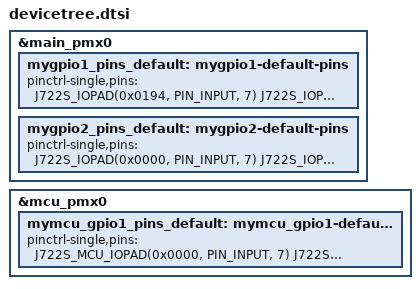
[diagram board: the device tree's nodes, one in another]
/* This file was auto-generated by TI PinMux on 6/7/2024 at 3:31:34 PM. */
/* This file should only be used as a reference. Some pins/peripherals, */
/* depending on your use case, may need additional configuration. */

&main_pmx0 {
	mygpio1_pins_default: mygpio1-default-pins {
		pinctrl-single,pins = <
			J722S_IOPAD(0x0194, PIN_INPUT, 7) /* (A25) MCASP0_AXR3.GPIO1_7 */
			J722S_IOPAD(0x0198, PIN_INPUT, 7) /* (A26) MCASP0_AXR2.GPIO1_8 */
			J722S_IOPAD(0x019c, PIN_INPUT, 7) /* (B25) MCASP0_AXR1.GPIO1_9 */
			J722S_IOPAD(0x01a0, PIN_INPUT, 7) /* (F23) MCASP0_AXR0.GPIO1_10 */
			J722S_IOPAD(0x01a4, PIN_INPUT, 7) /* (D25) MCASP0_ACLKX.GPIO1_11 */
			J722S_IOPAD(0x01a8, PIN_INPUT, 7) /* (C26) MCASP0_AFSX.GPIO1_12 */
			J722S_IOPAD(0x01ac, PIN_INPUT, 7) /* (C27) MCASP0_AFSR.GPIO1_13 */
			J722S_IOPAD(0x01b0, PIN_INPUT, 7) /* (F24) MCASP0_ACLKR.GPIO1_14 */
			J722S_IOPAD(0x01b4, PIN_INPUT, 7) /* (B20) SPI0_CS0.GPIO1_15 */
			J722S_IOPAD(0x01b8, PIN_INPUT, 7) /* (C20) SPI0_CS1.GPIO1_16 */
			J722S_IOPAD(0x01bc, PIN_INPUT, 7) /* (D20) SPI0_CLK.GPIO1_17 */
			J722S_IOPAD(0x01c0, PIN_INPUT, 7) /* (E19) SPI0_D0.GPIO1_18 */
			J722S_IOPAD(0x01c4, PIN_INPUT, 7) /* (E20) SPI0_D1.GPIO1_19 */
			J722S_IOPAD(0x01c8, PIN_INPUT, 7) /* (F19) UART0_RXD.GPIO1_20 */
			J722S_IOPAD(0x01cc, PIN_INPUT, 7) /* (F20) UART0_TXD.GPIO1_21 */
			J722S_IOPAD(0x01d0, PIN_INPUT, 7) /* (E22) UART0_CTSn.GPIO1_22 */
			J722S_IOPAD(0x01d4, PIN_INPUT, 7) /* (B21) UART0_RTSn.GPIO1_23 */
			J722S_IOPAD(0x01d8, PIN_INPUT, 7) /* (D22) MCAN0_TX.GPIO1_24 */
			J722S_IOPAD(0x01dc, PIN_INPUT, 7) /* (C22) MCAN0_RX.GPIO1_25 */
			J722S_IOPAD(0x01e0, PIN_INPUT, 7) /* (D23) I2C0_SCL.GPIO1_26 */
			J722S_IOPAD(0x01e4, PIN_INPUT, 7) /* (B22) I2C0_SDA.GPIO1_27 */
			J722S_IOPAD(0x01e8, PIN_INPUT, 7) /* (C24) I2C1_SCL.GPIO1_28 */
			J722S_IOPAD(0x01ec, PIN_INPUT, 7) /* (A22) I2C1_SDA.GPIO1_29 */
			J722S_IOPAD(0x01f0, PIN_INPUT, 7) /* (A23) EXT_REFCLK1.GPIO1_30 */
			J722S_IOPAD(0x01f4, PIN_INPUT, 7) /* (B23) EXTINTn.GPIO1_31 */
			J722S_IOPAD(0x0224, PIN_INPUT, 7) /* (H25) MMC1_DAT3.GPIO1_42 */
			J722S_IOPAD(0x0228, PIN_INPUT, 7) /* (J23) MMC1_DAT2.GPIO1_43 */
			J722S_IOPAD(0x022c, PIN_INPUT, 7) /* (H20) MMC1_DAT1.GPIO1_44 */
			J722S_IOPAD(0x0230, PIN_INPUT, 7) /* (H23) MMC1_DAT0.GPIO1_45 */
			J722S_IOPAD(0x0234, PIN_INPUT, 7) /* (H24) MMC1_CLK.GPIO1_46 */
			J722S_IOPAD(0x023c, PIN_INPUT, 7) /* (H22) MMC1_CMD.GPIO1_47 */
			J722S_IOPAD(0x0240, PIN_INPUT, 7) /* (B24) MMC1_SDCD.GPIO1_48 */
			J722S_IOPAD(0x0244, PIN_INPUT, 7) /* (A24) MMC1_SDWP.GPIO1_49 */
			J722S_IOPAD(0x0254, PIN_INPUT, 7) /* (E25) USB0_DRVVBUS.GPIO1_50 */
			J722S_IOPAD(0x0258, PIN_INPUT, 7) /* (B27) USB1_DRVVBUS.GPIO1_51 */
		>;
	};
	mygpio2_pins_default: mygpio2-default-pins {
		pinctrl-single,pins = <
			J722S_IOPAD(0x0000, PIN_INPUT, 7) /* (L24) OSPI0_CLK.GPIO0_0 */
			J722S_IOPAD(0x0004, PIN_INPUT, 7) /* (L23) OSPI0_LBCLKO.GPIO0_1 */
			J722S_IOPAD(0x0008, PIN_INPUT, 7) /* (L22) OSPI0_DQS.GPIO0_2 */
			J722S_IOPAD(0x000c, PIN_INPUT, 7) /* (K27) OSPI0_D0.GPIO0_3 */
			J722S_IOPAD(0x0010, PIN_INPUT, 7) /* (L27) OSPI0_D1.GPIO0_4 */
			J722S_IOPAD(0x0014, PIN_INPUT, 7) /* (L26) OSPI0_D2.GPIO0_5 */
			J722S_IOPAD(0x0018, PIN_INPUT, 7) /* (L25) OSPI0_D3.GPIO0_6 */
			J722S_IOPAD(0x001c, PIN_INPUT, 7) /* (L21) OSPI0_D4.GPIO0_7 */
			J722S_IOPAD(0x0020, PIN_INPUT, 7) /* (M26) OSPI0_D5.GPIO0_8 */
			J722S_IOPAD(0x0024, PIN_INPUT, 7) /* (N27) OSPI0_D6.GPIO0_9 */
			J722S_IOPAD(0x0028, PIN_INPUT, 7) /* (M27) OSPI0_D7.GPIO0_10 */
			J722S_IOPAD(0x002c, PIN_INPUT, 7) /* (K26) OSPI0_CSn0.GPIO0_11 */
			J722S_IOPAD(0x0030, PIN_INPUT, 7) /* (K23) OSPI0_CSn1.GPIO0_12 */
			J722S_IOPAD(0x0034, PIN_INPUT, 7) /* (K22) OSPI0_CSn2.GPIO0_13 */
			J722S_IOPAD(0x0038, PIN_INPUT, 7) /* (J22) OSPI0_CSn3.GPIO0_14 */
			J722S_IOPAD(0x003c, PIN_INPUT, 7) /* (R22) GPMC0_AD0.GPIO0_15 */
			J722S_IOPAD(0x0040, PIN_INPUT, 7) /* (R23) GPMC0_AD1.GPIO0_16 */
			J722S_IOPAD(0x0044, PIN_INPUT, 7) /* (R26) GPMC0_AD2.GPIO0_17 */
			J722S_IOPAD(0x0048, PIN_INPUT, 7) /* (T27) GPMC0_AD3.GPIO0_18 */
			J722S_IOPAD(0x004c, PIN_INPUT, 7) /* (T25) GPMC0_AD4.GPIO0_19 */
			J722S_IOPAD(0x0050, PIN_INPUT, 7) /* (T24) GPMC0_AD5.GPIO0_20 */
			J722S_IOPAD(0x0054, PIN_INPUT, 7) /* (T21) GPMC0_AD6.GPIO0_21 */
			J722S_IOPAD(0x0058, PIN_INPUT, 7) /* (T22) GPMC0_AD7.GPIO0_22 */
			J722S_IOPAD(0x005c, PIN_INPUT, 7) /* (U27) GPMC0_AD8.GPIO0_23 */
			J722S_IOPAD(0x0060, PIN_INPUT, 7) /* (U26) GPMC0_AD9.GPIO0_24 */
			J722S_IOPAD(0x0064, PIN_INPUT, 7) /* (V27) GPMC0_AD10.GPIO0_25 */
			J722S_IOPAD(0x0068, PIN_INPUT, 7) /* (V25) GPMC0_AD11.GPIO0_26 */
			J722S_IOPAD(0x006c, PIN_INPUT, 7) /* (V26) GPMC0_AD12.GPIO0_27 */
			J722S_IOPAD(0x0070, PIN_INPUT, 7) /* (V24) GPMC0_AD13.GPIO0_28 */
			J722S_IOPAD(0x0074, PIN_INPUT, 7) /* (V22) GPMC0_AD14.GPIO0_29 */
			J722S_IOPAD(0x0078, PIN_INPUT, 7) /* (V23) GPMC0_AD15.GPIO0_30 */
			J722S_IOPAD(0x007c, PIN_INPUT, 7) /* (T23) GPMC0_CLK.GPIO0_31 */
			J722S_IOPAD(0x0084, PIN_INPUT, 7) /* (N21) GPMC0_ADVn_ALE.GPIO0_32 */
			J722S_IOPAD(0x0088, PIN_INPUT, 7) /* (N22) GPMC0_OEn_REn.GPIO0_33 */
			J722S_IOPAD(0x008c, PIN_INPUT, 7) /* (N23) GPMC0_WEn.GPIO0_34 */
			J722S_IOPAD(0x0090, PIN_INPUT, 7) /* (P27) GPMC0_BE0n_CLE.GPIO0_35 */
			J722S_IOPAD(0x0094, PIN_INPUT, 7) /* (P26) GPMC0_BE1n.GPIO0_36 */
			J722S_IOPAD(0x0098, PIN_INPUT, 7) /* (V21) GPMC0_WAIT0.GPIO0_37 */
			J722S_IOPAD(0x009c, PIN_INPUT, 7) /* (W26) GPMC0_WAIT1.GPIO0_38 */
			J722S_IOPAD(0x00a0, PIN_INPUT, 7) /* (N24) GPMC0_WPn.GPIO0_39 */
			J722S_IOPAD(0x00a4, PIN_INPUT, 7) /* (N25) GPMC0_DIR.GPIO0_40 */
			J722S_IOPAD(0x00a8, PIN_INPUT, 7) /* (R27) GPMC0_CSn0.GPIO0_41 */
			J722S_IOPAD(0x00ac, PIN_INPUT, 7) /* (P21) GPMC0_CSn1.GPIO0_42 */
			J722S_IOPAD(0x00b0, PIN_INPUT, 7) /* (P22) GPMC0_CSn2.GPIO0_43 */
			J722S_IOPAD(0x00b4, PIN_INPUT, 7) /* (P23) GPMC0_CSn3.GPIO0_44 */
			J722S_IOPAD(0x00b8, PIN_INPUT, 7) /* (W27) VOUT0_DATA0.GPIO0_45 */
			J722S_IOPAD(0x00bc, PIN_INPUT, 7) /* (W25) VOUT0_DATA1.GPIO0_46 */
			J722S_IOPAD(0x00c0, PIN_INPUT, 7) /* (W24) VOUT0_DATA2.GPIO0_47 */
			J722S_IOPAD(0x00c4, PIN_INPUT, 7) /* (W23) VOUT0_DATA3.GPIO0_48 */
			J722S_IOPAD(0x00c8, PIN_INPUT, 7) /* (W22) VOUT0_DATA4.GPIO0_49 */
			J722S_IOPAD(0x00cc, PIN_INPUT, 7) /* (W21) VOUT0_DATA5.GPIO0_50 */
			J722S_IOPAD(0x00d0, PIN_INPUT, 7) /* (Y26) VOUT0_DATA6.GPIO0_51 */
			J722S_IOPAD(0x00d4, PIN_INPUT, 7) /* (Y27) VOUT0_DATA7.GPIO0_52 */
			J722S_IOPAD(0x00d8, PIN_INPUT, 7) /* (AA24) VOUT0_DATA8.GPIO0_53 */
			J722S_IOPAD(0x00dc, PIN_INPUT, 7) /* (AA27) VOUT0_DATA9.GPIO0_54 */
			J722S_IOPAD(0x00e0, PIN_INPUT, 7) /* (AA25) VOUT0_DATA10.GPIO0_55 */
			J722S_IOPAD(0x00e4, PIN_INPUT, 7) /* (AB25) VOUT0_DATA11.GPIO0_56 */
			J722S_IOPAD(0x00e8, PIN_INPUT, 7) /* (AA23) VOUT0_DATA12.GPIO0_57 */
			J722S_IOPAD(0x00ec, PIN_INPUT, 7) /* (AA22) VOUT0_DATA13.GPIO0_58 */
			J722S_IOPAD(0x00f0, PIN_INPUT, 7) /* (AB26) VOUT0_DATA14.GPIO0_59 */
			J722S_IOPAD(0x00f4, PIN_INPUT, 7) /* (AB27) VOUT0_DATA15.GPIO0_60 */
			J722S_IOPAD(0x00f8, PIN_INPUT, 7) /* (AB24) VOUT0_HSYNC.GPIO0_61 */
			J722S_IOPAD(0x00fc, PIN_INPUT, 7) /* (AC27) VOUT0_DE.GPIO0_62 */
			J722S_IOPAD(0x0100, PIN_INPUT, 7) /* (AB23) VOUT0_VSYNC.GPIO0_63 */
			J722S_IOPAD(0x0104, PIN_INPUT, 7) /* (AC26) VOUT0_PCLK.GPIO0_64 */
			J722S_IOPAD(0x0108, PIN_INPUT, 7) /* (J27) MMC2_DAT3.GPIO0_65 */
			J722S_IOPAD(0x010c, PIN_INPUT, 7) /* (H27) MMC2_DAT2.GPIO0_66 */
			J722S_IOPAD(0x0110, PIN_INPUT, 7) /* (G27) MMC2_DAT1.GPIO0_67 */
			J722S_IOPAD(0x0114, PIN_INPUT, 7) /* (G26) MMC2_DAT0.GPIO0_68 */
			J722S_IOPAD(0x0118, PIN_INPUT, 7) /* (H26) MMC2_CLK.GPIO0_69 */
			J722S_IOPAD(0x0120, PIN_INPUT, 7) /* (F27) MMC2_CMD.GPIO0_70 */
			J722S_IOPAD(0x0124, PIN_INPUT, 7) /* (F26) MMC2_SDCD.GPIO0_71 */
			J722S_IOPAD(0x0128, PIN_INPUT, 7) /* (H21) MMC2_SDWP.GPIO0_72 */
			J722S_IOPAD(0x012c, PIN_INPUT, 7) /* (AF25) RGMII1_TX_CTL.GPIO0_73 */
			J722S_IOPAD(0x0130, PIN_INPUT, 7) /* (AG26) RGMII1_TXC.GPIO0_74 */
			J722S_IOPAD(0x0134, PIN_INPUT, 7) /* (AF27) RGMII1_TD0.GPIO0_75 */
			J722S_IOPAD(0x0138, PIN_INPUT, 7) /* (AE23) RGMII1_TD1.GPIO0_76 */
			J722S_IOPAD(0x013c, PIN_INPUT, 7) /* (AG25) RGMII1_TD2.GPIO0_77 */
			J722S_IOPAD(0x0140, PIN_INPUT, 7) /* (AF24) RGMII1_TD3.GPIO0_78 */
			J722S_IOPAD(0x0144, PIN_INPUT, 7) /* (AD23) RGMII1_RX_CTL.GPIO0_79 */
			J722S_IOPAD(0x0148, PIN_INPUT, 7) /* (AE27) RGMII1_RXC.GPIO0_80 */
			J722S_IOPAD(0x014c, PIN_INPUT, 7) /* (AC25) RGMII1_RD0.GPIO0_81 */
			J722S_IOPAD(0x0150, PIN_INPUT, 7) /* (AD27) RGMII1_RD1.GPIO0_82 */
			J722S_IOPAD(0x0154, PIN_INPUT, 7) /* (AE24) RGMII1_RD2.GPIO0_83 */
			J722S_IOPAD(0x0158, PIN_INPUT, 7) /* (AE26) RGMII1_RD3.GPIO0_84 */
			J722S_IOPAD(0x015c, PIN_INPUT, 7) /* (AD25) MDIO0_MDIO.GPIO0_85 */
			J722S_IOPAD(0x0160, PIN_INPUT, 7) /* (AC24) MDIO0_MDC.GPIO0_86 */
		>;
	};
};

&mcu_pmx0 {
	mymcu_gpio1_pins_default: mymcu_gpio1-default-pins {
		pinctrl-single,pins = <
			J722S_MCU_IOPAD(0x0000, PIN_INPUT, 7) /* (C12) MCU_SPI0_CS0.MCU_GPIO0_0 */
			J722S_MCU_IOPAD(0x0004, PIN_INPUT, 7) /* (A10) MCU_SPI0_CS1.MCU_GPIO0_1 */
			J722S_MCU_IOPAD(0x0008, PIN_INPUT, 7) /* (A9) MCU_SPI0_CLK.MCU_GPIO0_2 */
			J722S_MCU_IOPAD(0x000c, PIN_INPUT, 7) /* (B12) MCU_SPI0_D0.MCU_GPIO0_3 */
			J722S_MCU_IOPAD(0x0010, PIN_INPUT, 7) /* (C11) MCU_SPI0_D1.MCU_GPIO0_4 */
			J722S_MCU_IOPAD(0x0014, PIN_INPUT, 7) /* (B8) MCU_UART0_RXD.MCU_GPIO0_5 */
			J722S_MCU_IOPAD(0x0018, PIN_INPUT, 7) /* (B4) MCU_UART0_TXD.MCU_GPIO0_6 */
			J722S_MCU_IOPAD(0x001c, PIN_INPUT, 7) /* (B5) MCU_UART0_CTSn.MCU_GPIO0_7 */
			J722S_MCU_IOPAD(0x0020, PIN_INPUT, 7) /* (C5) MCU_UART0_RTSn.MCU_GPIO0_8 */
			J722S_MCU_IOPAD(0x0024, PIN_INPUT, 7) /* (B3) WKUP_UART0_RXD.MCU_GPIO0_9 */
			J722S_MCU_IOPAD(0x0028, PIN_INPUT, 7) /* (C8) WKUP_UART0_TXD.MCU_GPIO0_10 */
			J722S_MCU_IOPAD(0x002c, PIN_INPUT, 7) /* (C4) WKUP_UART0_CTSn.MCU_GPIO0_11 */
			J722S_MCU_IOPAD(0x0030, PIN_INPUT, 7) /* (C3) WKUP_UART0_RTSn.MCU_GPIO0_12 */
			J722S_MCU_IOPAD(0x0034, PIN_INPUT, 7) /* (B2) MCU_MCAN0_TX.MCU_GPIO0_13 */
			J722S_MCU_IOPAD(0x0038, PIN_INPUT, 7) /* (D8) MCU_MCAN0_RX.MCU_GPIO0_14 */
			J722S_MCU_IOPAD(0x003c, PIN_INPUT, 7) /* (C1) MCU_MCAN1_TX.MCU_GPIO0_15 */
			J722S_MCU_IOPAD(0x0040, PIN_INPUT, 7) /* (B1) MCU_MCAN1_RX.MCU_GPIO0_16 */
			J722S_MCU_IOPAD(0x0044, PIN_INPUT, 7) /* (B13) MCU_I2C0_SCL.MCU_GPIO0_17 */
			J722S_MCU_IOPAD(0x0048, PIN_INPUT, 7) /* (E11) MCU_I2C0_SDA.MCU_GPIO0_18 */
			J722S_MCU_IOPAD(0x004c, PIN_INPUT, 7) /* (B9) WKUP_I2C0_SCL.MCU_GPIO0_19 */
			J722S_MCU_IOPAD(0x0050, PIN_INPUT, 7) /* (D11) WKUP_I2C0_SDA.MCU_GPIO0_20 */
			J722S_MCU_IOPAD(0x005c, PIN_INPUT, 7) /* (E13) MCU_RESETSTATz.MCU_GPIO0_21 */
			J722S_MCU_IOPAD(0x0080, PIN_INPUT, 7) /* (A8) PMIC_LPM_EN0.MCU_GPIO0_22 */
			J722S_MCU_IOPAD(0x0084, PIN_INPUT, 7) /* (F12) WKUP_CLKOUT0.MCU_GPIO0_23 */
		>;
	};
};
